# STM8AF52AA register map
Vendor: STMicroelectronics; Series: STM8S/STM8AF, high density; File version: 1.0
Automotive 8-bit MCU with 128 Kbytes Flash, LIN, CAN, 24 MHz CPU, integrated EEPROM
CPU: other r1p0, big endian, no MPU, no FPU, 4 interrupt priority bits
Registers are 8-bit, read-write, reset 0x0 unless marked. A register's access mark holds for its fields unless they carry their own. Offsets are from the block's base; lines under a group give offsets from that group; [hi:lo] are bit positions; {n}, {i} and the like mark numbered series; 'fields as' and 'values as' point back to an identical list; <NAME> marks a mode.

## Memory map
0x00004800 OPT blocks up to offset 0x80
0x00005000 PORTA size 0x5
0x00005005 PORTB size 0x5
0x0000500A PORTC size 0x5
0x0000500F PORTD size 0x5
0x00005014 PORTE size 0x5
0x00005019 PORTF size 0x5
0x0000501E PORTG size 0x5
0x00005023 PORTH size 0x5
0x00005028 PORTI size 0x5
0x0000505A FLASH blocks up to offset 0xB
0x000050A0 ITC blocks up to offset 0x2ED7
0x000050C0 CLK blocks up to offset 0xE
0x000050D1 WWDG size 0x2
0x000050E0 IWDG size 0x3
0x000050F0 AWU size 0x3
0x000050F3 BEEP size 0x1
0x00005200 SPI size 0x8
0x00005210 I2C blocks up to offset 0xE
0x00005230 USART size 0x8
0x00005240 LINUART blocks up to offset 0xA
0x00005250 TIM1 size 0x20
0x00005300 TIM2 size 0x15
0x00005320 TIM3 size 0x11
0x00005340 TIM4 size 0x7
0x00005400 ADC blocks up to offset 0x8
0x00005420 CAN size 0x18
0x00005800 TMU size 0x9
0x00007F00 CPU blocks up to offset 0x61
0x00007F80 SWIM size 0x1
0x00007F90 DM size 0xB

## Interrupts
1 Interrupt_IRQ1 (AWU) — Interrupt_IRQ1 interrupt
2 Interrupt_IRQ2 (CLK, ITC) — Interrupt_IRQ2 interrupt
8 Interrupt_IRQ8 (CAN) — Interrupt_IRQ8 interrupt
9 Interrupt_IRQ9 (CAN) — Interrupt_IRQ9 interrupt
10 Interrupt_IRQ10 (SPI) — Interrupt_IRQ10 interrupt
11 Interrupt_IRQ11 (TIM1) — Interrupt_IRQ11 interrupt
12 Interrupt_IRQ12 (TIM1) — Interrupt_IRQ12 interrupt
13 Interrupt_IRQ13 (TIM2) — Interrupt_IRQ13 interrupt
14 Interrupt_IRQ14 (TIM2) — Interrupt_IRQ14 interrupt
15 Interrupt_IRQ15 (TIM3) — Interrupt_IRQ15 interrupt
16 Interrupt_IRQ16 (TIM3) — Interrupt_IRQ16 interrupt
17 Interrupt_IRQ17 (USART) — Interrupt_IRQ17 interrupt
18 Interrupt_IRQ18 (USART) — Interrupt_IRQ18 interrupt
19 Interrupt_IRQ19 (I2C) — Interrupt_IRQ19 interrupt
20 Interrupt_IRQ20 (LINUART) — Interrupt_IRQ20 interrupt
21 Interrupt_IRQ21 (LINUART) — Interrupt_IRQ21 interrupt
22 Interrupt_IRQ22 (ADC) — Interrupt_IRQ22 interrupt
23 Interrupt_IRQ23 (TIM4) — Interrupt_IRQ23 interrupt
24 Interrupt_IRQ24 (FLASH) — Interrupt_IRQ24 interrupt

## ADC
Base 0x00005400
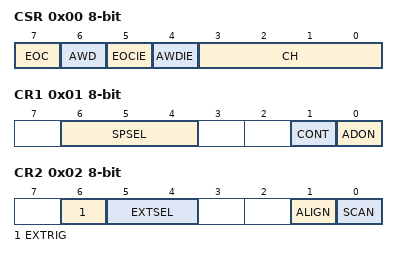
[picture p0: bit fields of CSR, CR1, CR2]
0x00 CSR — ADC control/status register
  [7] EOC, [6] AWD, [5] EOCIE, [4] AWDIE, [3:0] CH
0x01 CR1 — ADC configuration register 1
  [6:4] SPSEL, [1] CONT, [0] ADON
0x02 CR2 — ADC configuration register 2
  [6] EXTRIG, [5:4] EXTSEL, [1] ALIGN, [0] SCAN
0x04 DRH — ADC data register high
  [7:0] DATA
0x05 DRL — ADC data register low
  [7:6] DATA
0x06 TDRH — ADC schmitt trigger disable register high
  [7:0] TD
0x07 TDRL — ADC schmitt trigger disable register low
  [7:0] TD

## AWU
Base 0x000050F0
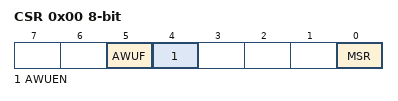
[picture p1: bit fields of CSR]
0x00 CSR — AWU control/status register 1
  [5] AWUF, [4] AWUEN, [0] MSR
0x01 APR reset 0x3F — AWU asynchronous prescaler buffer register
  [5:0] APR
0x02 TBR — AWU timebase selection register
  [3:0] AWUTB

## BEEP
Base 0x000050F3
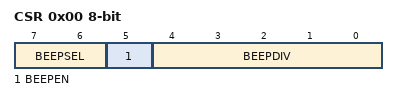
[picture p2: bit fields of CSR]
0x00 CSR — BEEP control/status register
  [7:6] BEEPSEL, [5] BEEPEN, [4:0] BEEPDIV

## CAN
Base 0x00005420
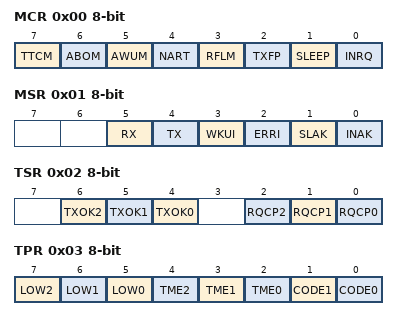
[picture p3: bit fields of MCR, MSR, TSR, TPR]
0x00 MCR — CAN master control register
  [7] TTCM, [6] ABOM, [5] AWUM, [4] NART, [3] RFLM, [2] TXFP, [1] SLEEP, [0] INRQ
0x01 MSR — CAN master status register
  [5] RX, [4] TX, [3] WKUI, [2] ERRI, [1] SLAK, [0] INAK
0x02 TSR — CAN transmit status register
  [6] TXOK2, [5] TXOK1, [4] TXOK0, [2] RQCP2, [1] RQCP1, [0] RQCP0
0x03 TPR — CAN transmit priority register
  [7] LOW2, [6] LOW1, [5] LOW0, [4] TME2, [3] TME1, [2] TME0, [1] CODE1, [0] CODE0
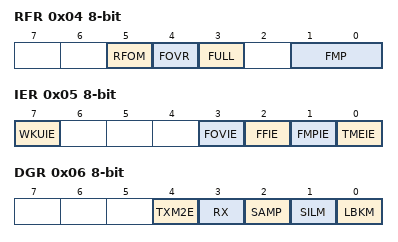
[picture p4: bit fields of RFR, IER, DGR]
0x04 RFR — CAN receive FIFO register
  [5] RFOM, [4] FOVR, [3] FULL, [1:0] FMP
0x05 IER — CAN interrupt enable register
  [7] WKUIE, [3] FOVIE, [2] FFIE, [1] FMPIE, [0] TMEIE
0x06 DGR — CAN diagnosis register
  [4] TXM2E, [3] RX, [2] SAMP, [1] SILM, [0] LBKM
0x07 PSR — CAN page selection register
  [2:0] PS
{0x8+i} P{i} (i=0..9) — CAN paged register {i} N/A
0x12 PA — CAN paged register A N/A
0x13 PB — CAN paged register B N/A
0x14 PC — CAN paged register C N/A
0x15 PD — CAN paged register D N/A
0x16 PE — CAN paged register E N/A
0x17 PF — CAN paged register F N/A
